VERSION ""

NS_ :

BS_:

BU_: RADAR

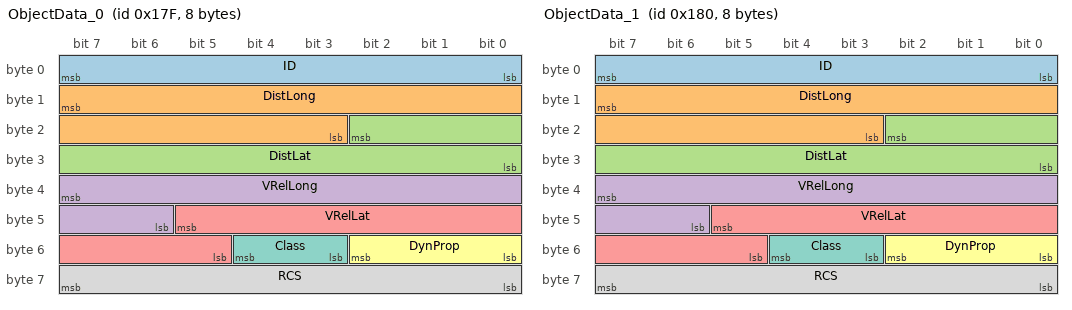
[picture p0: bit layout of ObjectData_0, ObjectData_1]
BO_ 383 ObjectData_0: 8 RADAR
 SG_ ID : 7|8@0+ (1,0) [0|255] "" XXX
 SG_ DistLong : 15|13@0+ (0.2,-500) [-500|1138.2] "m" XXX
 SG_ DistLat : 18|11@0+ (0.2,-204.6) [-204.6|204.8] "m" XXX
 SG_ VRelLong : 39|10@0+ (0.25,-128) [-128|127.75] "m/s" XXX
 SG_ VRelLat : 45|9@0+ (0.25,-64) [-64|63.75] "m/s" XXX
 SG_ DynProp : 50|3@0+ (1,0) [0|7] "" XXX
 SG_ Class : 52|2@0+ (1,0) [0|3] "" XXX
 SG_ RCS : 63|8@0+ (0.5,-64) [-64|63.75] "dBm2" XXX

BO_ 384 ObjectData_1: 8 RADAR
 SG_ ID : 7|8@0+ (1,0) [0|255] "" XXX
 SG_ DistLong : 15|13@0+ (0.2,-500) [-500|1138.2] "m" XXX
 SG_ DistLat : 18|11@0+ (0.2,-204.6) [-204.6|204.8] "m" XXX
 SG_ VRelLong : 39|10@0+ (0.25,-128) [-128|127.75] "m/s" XXX
 SG_ VRelLat : 45|9@0+ (0.25,-64) [-64|63.75] "m/s" XXX
 SG_ DynProp : 50|3@0+ (1,0) [0|7] "" XXX
 SG_ Class : 52|2@0+ (1,0) [0|3] "" XXX
 SG_ RCS : 63|8@0+ (0.5,-64) [-64|63.75] "dBm2" XXX

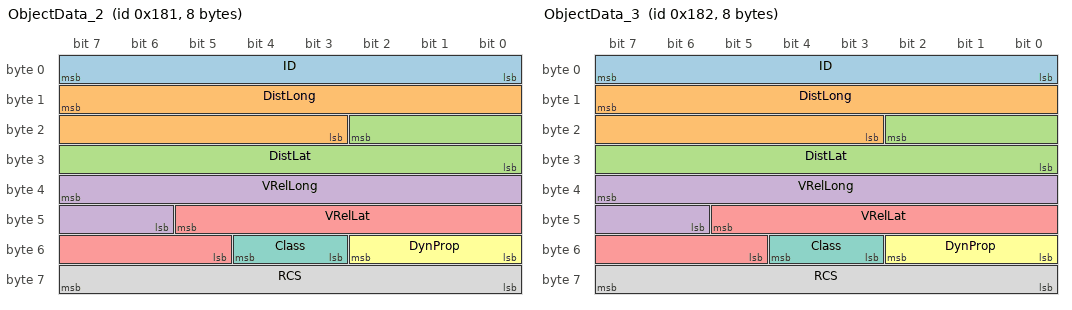
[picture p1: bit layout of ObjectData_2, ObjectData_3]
BO_ 385 ObjectData_2: 8 RADAR
 SG_ ID : 7|8@0+ (1,0) [0|255] "" XXX
 SG_ DistLong : 15|13@0+ (0.2,-500) [-500|1138.2] "m" XXX
 SG_ DistLat : 18|11@0+ (0.2,-204.6) [-204.6|204.8] "m" XXX
 SG_ VRelLong : 39|10@0+ (0.25,-128) [-128|127.75] "m/s" XXX
 SG_ VRelLat : 45|9@0+ (0.25,-64) [-64|63.75] "m/s" XXX
 SG_ DynProp : 50|3@0+ (1,0) [0|7] "" XXX
 SG_ Class : 52|2@0+ (1,0) [0|3] "" XXX
 SG_ RCS : 63|8@0+ (0.5,-64) [-64|63.75] "dBm2" XXX

BO_ 386 ObjectData_3: 8 RADAR
 SG_ ID : 7|8@0+ (1,0) [0|255] "" XXX
 SG_ DistLong : 15|13@0+ (0.2,-500) [-500|1138.2] "m" XXX
 SG_ DistLat : 18|11@0+ (0.2,-204.6) [-204.6|204.8] "m" XXX
 SG_ VRelLong : 39|10@0+ (0.25,-128) [-128|127.75] "m/s" XXX
 SG_ VRelLat : 45|9@0+ (0.25,-64) [-64|63.75] "m/s" XXX
 SG_ DynProp : 50|3@0+ (1,0) [0|7] "" XXX
 SG_ Class : 52|2@0+ (1,0) [0|3] "" XXX
 SG_ RCS : 63|8@0+ (0.5,-64) [-64|63.75] "dBm2" XXX

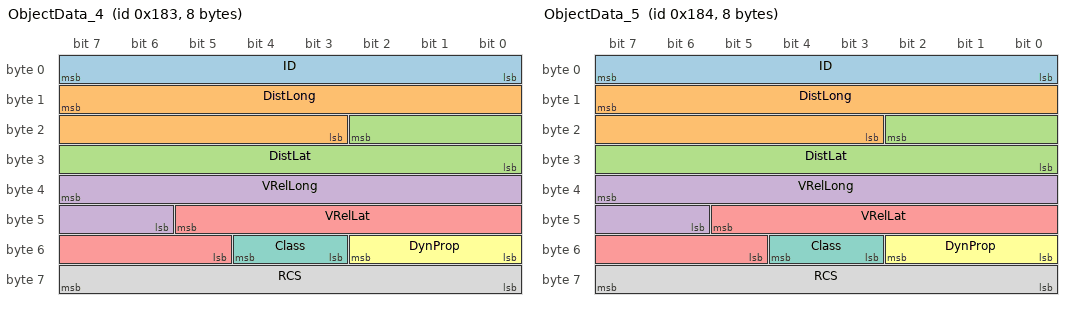
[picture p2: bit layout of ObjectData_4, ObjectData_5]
BO_ 387 ObjectData_4: 8 RADAR
 SG_ ID : 7|8@0+ (1,0) [0|255] "" XXX
 SG_ DistLong : 15|13@0+ (0.2,-500) [-500|1138.2] "m" XXX
 SG_ DistLat : 18|11@0+ (0.2,-204.6) [-204.6|204.8] "m" XXX
 SG_ VRelLong : 39|10@0+ (0.25,-128) [-128|127.75] "m/s" XXX
 SG_ VRelLat : 45|9@0+ (0.25,-64) [-64|63.75] "m/s" XXX
 SG_ DynProp : 50|3@0+ (1,0) [0|7] "" XXX
 SG_ Class : 52|2@0+ (1,0) [0|3] "" XXX
 SG_ RCS : 63|8@0+ (0.5,-64) [-64|63.75] "dBm2" XXX

BO_ 388 ObjectData_5: 8 RADAR
 SG_ ID : 7|8@0+ (1,0) [0|255] "" XXX
 SG_ DistLong : 15|13@0+ (0.2,-500) [-500|1138.2] "m" XXX
 SG_ DistLat : 18|11@0+ (0.2,-204.6) [-204.6|204.8] "m" XXX
 SG_ VRelLong : 39|10@0+ (0.25,-128) [-128|127.75] "m/s" XXX
 SG_ VRelLat : 45|9@0+ (0.25,-64) [-64|63.75] "m/s" XXX
 SG_ DynProp : 50|3@0+ (1,0) [0|7] "" XXX
 SG_ Class : 52|2@0+ (1,0) [0|3] "" XXX
 SG_ RCS : 63|8@0+ (0.5,-64) [-64|63.75] "dBm2" XXX

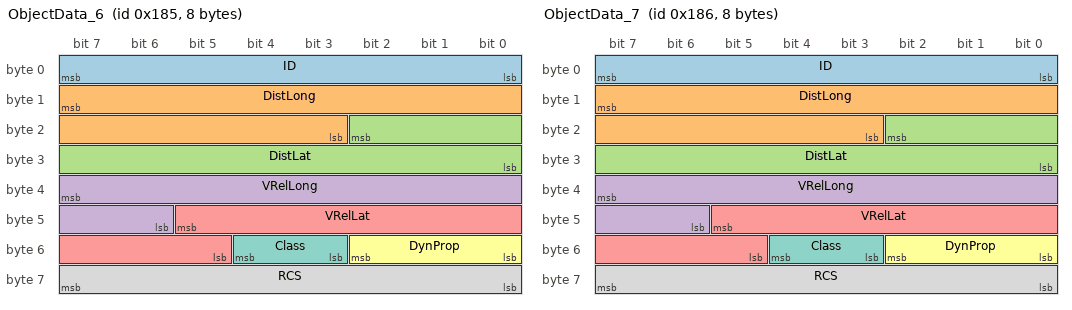
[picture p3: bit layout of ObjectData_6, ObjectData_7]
BO_ 389 ObjectData_6: 8 RADAR
 SG_ ID : 7|8@0+ (1,0) [0|255] "" XXX
 SG_ DistLong : 15|13@0+ (0.2,-500) [-500|1138.2] "m" XXX
 SG_ DistLat : 18|11@0+ (0.2,-204.6) [-204.6|204.8] "m" XXX
 SG_ VRelLong : 39|10@0+ (0.25,-128) [-128|127.75] "m/s" XXX
 SG_ VRelLat : 45|9@0+ (0.25,-64) [-64|63.75] "m/s" XXX
 SG_ DynProp : 50|3@0+ (1,0) [0|7] "" XXX
 SG_ Class : 52|2@0+ (1,0) [0|3] "" XXX
 SG_ RCS : 63|8@0+ (0.5,-64) [-64|63.75] "dBm2" XXX

BO_ 390 ObjectData_7: 8 RADAR
 SG_ ID : 7|8@0+ (1,0) [0|255] "" XXX
 SG_ DistLong : 15|13@0+ (0.2,-500) [-500|1138.2] "m" XXX
 SG_ DistLat : 18|11@0+ (0.2,-204.6) [-204.6|204.8] "m" XXX
 SG_ VRelLong : 39|10@0+ (0.25,-128) [-128|127.75] "m/s" XXX
 SG_ VRelLat : 45|9@0+ (0.25,-64) [-64|63.75] "m/s" XXX
 SG_ DynProp : 50|3@0+ (1,0) [0|7] "" XXX
 SG_ Class : 52|2@0+ (1,0) [0|3] "" XXX
 SG_ RCS : 63|8@0+ (0.5,-64) [-64|63.75] "dBm2" XXX

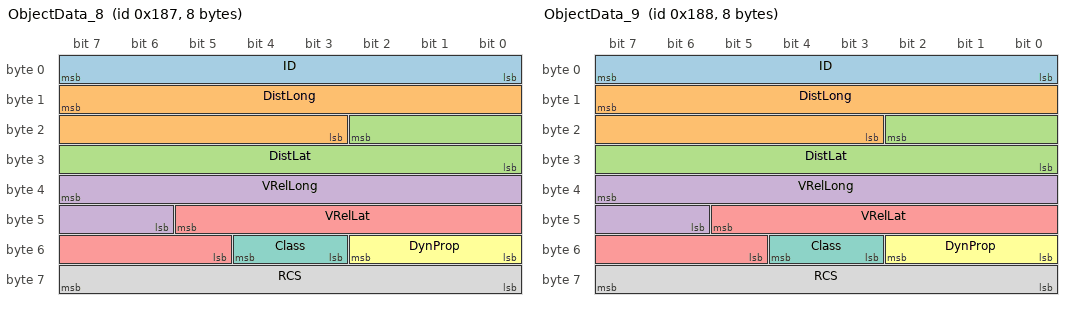
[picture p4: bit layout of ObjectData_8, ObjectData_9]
BO_ 391 ObjectData_8: 8 RADAR
 SG_ ID : 7|8@0+ (1,0) [0|255] "" XXX
 SG_ DistLong : 15|13@0+ (0.2,-500) [-500|1138.2] "m" XXX
 SG_ DistLat : 18|11@0+ (0.2,-204.6) [-204.6|204.8] "m" XXX
 SG_ VRelLong : 39|10@0+ (0.25,-128) [-128|127.75] "m/s" XXX
 SG_ VRelLat : 45|9@0+ (0.25,-64) [-64|63.75] "m/s" XXX
 SG_ DynProp : 50|3@0+ (1,0) [0|7] "" XXX
 SG_ Class : 52|2@0+ (1,0) [0|3] "" XXX
 SG_ RCS : 63|8@0+ (0.5,-64) [-64|63.75] "dBm2" XXX

BO_ 392 ObjectData_9: 8 RADAR
 SG_ ID : 7|8@0+ (1,0) [0|255] "" XXX
 SG_ DistLong : 15|13@0+ (0.2,-500) [-500|1138.2] "m" XXX
 SG_ DistLat : 18|11@0+ (0.2,-204.6) [-204.6|204.8] "m" XXX
 SG_ VRelLong : 39|10@0+ (0.25,-128) [-128|127.75] "m/s" XXX
 SG_ VRelLat : 45|9@0+ (0.25,-64) [-64|63.75] "m/s" XXX
 SG_ DynProp : 50|3@0+ (1,0) [0|7] "" XXX
 SG_ Class : 52|2@0+ (1,0) [0|3] "" XXX
 SG_ RCS : 63|8@0+ (0.5,-64) [-64|63.75] "dBm2" XXX

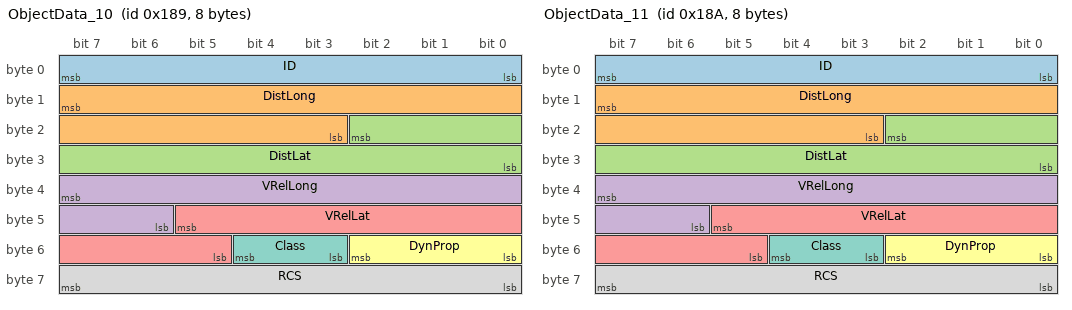
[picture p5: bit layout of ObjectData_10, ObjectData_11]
BO_ 393 ObjectData_10: 8 RADAR
 SG_ ID : 7|8@0+ (1,0) [0|255] "" XXX
 SG_ DistLong : 15|13@0+ (0.2,-500) [-500|1138.2] "m" XXX
 SG_ DistLat : 18|11@0+ (0.2,-204.6) [-204.6|204.8] "m" XXX
 SG_ VRelLong : 39|10@0+ (0.25,-128) [-128|127.75] "m/s" XXX
 SG_ VRelLat : 45|9@0+ (0.25,-64) [-64|63.75] "m/s" XXX
 SG_ DynProp : 50|3@0+ (1,0) [0|7] "" XXX
 SG_ Class : 52|2@0+ (1,0) [0|3] "" XXX
 SG_ RCS : 63|8@0+ (0.5,-64) [-64|63.75] "dBm2" XXX

BO_ 394 ObjectData_11: 8 RADAR
 SG_ ID : 7|8@0+ (1,0) [0|255] "" XXX
 SG_ DistLong : 15|13@0+ (0.2,-500) [-500|1138.2] "m" XXX
 SG_ DistLat : 18|11@0+ (0.2,-204.6) [-204.6|204.8] "m" XXX
 SG_ VRelLong : 39|10@0+ (0.25,-128) [-128|127.75] "m/s" XXX
 SG_ VRelLat : 45|9@0+ (0.25,-64) [-64|63.75] "m/s" XXX
 SG_ DynProp : 50|3@0+ (1,0) [0|7] "" XXX
 SG_ Class : 52|2@0+ (1,0) [0|3] "" XXX
 SG_ RCS : 63|8@0+ (0.5,-64) [-64|63.75] "dBm2" XXX

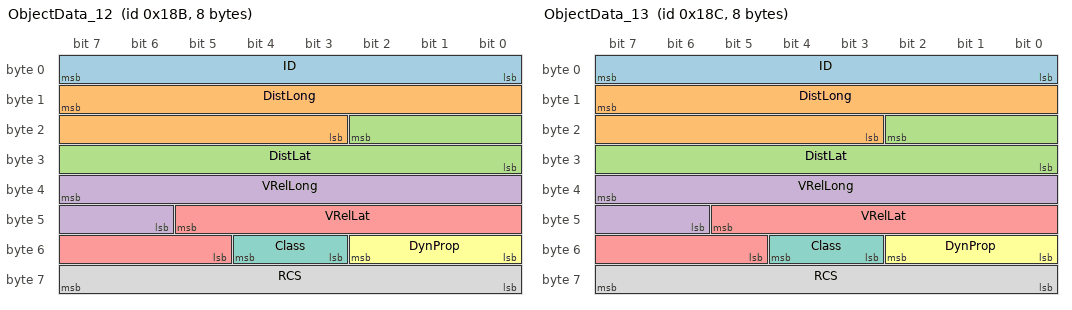
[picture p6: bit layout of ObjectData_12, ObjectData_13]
BO_ 395 ObjectData_12: 8 RADAR
 SG_ ID : 7|8@0+ (1,0) [0|255] "" XXX
 SG_ DistLong : 15|13@0+ (0.2,-500) [-500|1138.2] "m" XXX
 SG_ DistLat : 18|11@0+ (0.2,-204.6) [-204.6|204.8] "m" XXX
 SG_ VRelLong : 39|10@0+ (0.25,-128) [-128|127.75] "m/s" XXX
 SG_ VRelLat : 45|9@0+ (0.25,-64) [-64|63.75] "m/s" XXX
 SG_ DynProp : 50|3@0+ (1,0) [0|7] "" XXX
 SG_ Class : 52|2@0+ (1,0) [0|3] "" XXX
 SG_ RCS : 63|8@0+ (0.5,-64) [-64|63.75] "dBm2" XXX

BO_ 396 ObjectData_13: 8 RADAR
 SG_ ID : 7|8@0+ (1,0) [0|255] "" XXX
 SG_ DistLong : 15|13@0+ (0.2,-500) [-500|1138.2] "m" XXX
 SG_ DistLat : 18|11@0+ (0.2,-204.6) [-204.6|204.8] "m" XXX
 SG_ VRelLong : 39|10@0+ (0.25,-128) [-128|127.75] "m/s" XXX
 SG_ VRelLat : 45|9@0+ (0.25,-64) [-64|63.75] "m/s" XXX
 SG_ DynProp : 50|3@0+ (1,0) [0|7] "" XXX
 SG_ Class : 52|2@0+ (1,0) [0|3] "" XXX
 SG_ RCS : 63|8@0+ (0.5,-64) [-64|63.75] "dBm2" XXX

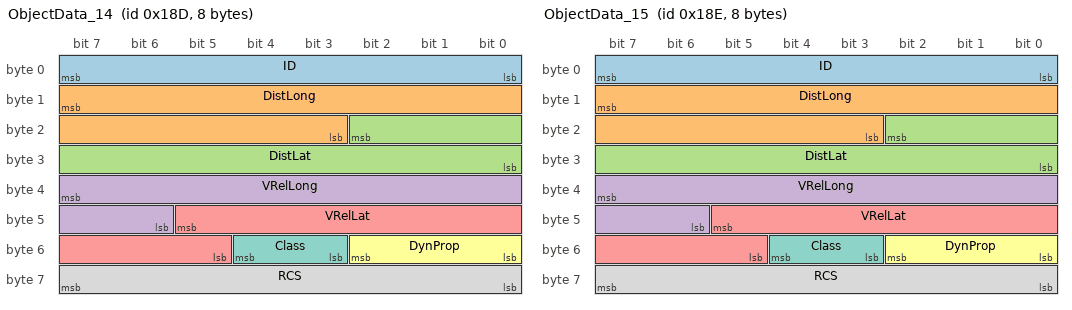
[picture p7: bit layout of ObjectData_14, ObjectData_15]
BO_ 397 ObjectData_14: 8 RADAR
 SG_ ID : 7|8@0+ (1,0) [0|255] "" XXX
 SG_ DistLong : 15|13@0+ (0.2,-500) [-500|1138.2] "m" XXX
 SG_ DistLat : 18|11@0+ (0.2,-204.6) [-204.6|204.8] "m" XXX
 SG_ VRelLong : 39|10@0+ (0.25,-128) [-128|127.75] "m/s" XXX
 SG_ VRelLat : 45|9@0+ (0.25,-64) [-64|63.75] "m/s" XXX
 SG_ DynProp : 50|3@0+ (1,0) [0|7] "" XXX
 SG_ Class : 52|2@0+ (1,0) [0|3] "" XXX
 SG_ RCS : 63|8@0+ (0.5,-64) [-64|63.75] "dBm2" XXX

BO_ 398 ObjectData_15: 8 RADAR
 SG_ ID : 7|8@0+ (1,0) [0|255] "" XXX
 SG_ DistLong : 15|13@0+ (0.2,-500) [-500|1138.2] "m" XXX
 SG_ DistLat : 18|11@0+ (0.2,-204.6) [-204.6|204.8] "m" XXX
 SG_ VRelLong : 39|10@0+ (0.25,-128) [-128|127.75] "m/s" XXX
 SG_ VRelLat : 45|9@0+ (0.25,-64) [-64|63.75] "m/s" XXX
 SG_ DynProp : 50|3@0+ (1,0) [0|7] "" XXX
 SG_ Class : 52|2@0+ (1,0) [0|3] "" XXX
 SG_ RCS : 63|8@0+ (0.5,-64) [-64|63.75] "dBm2" XXX

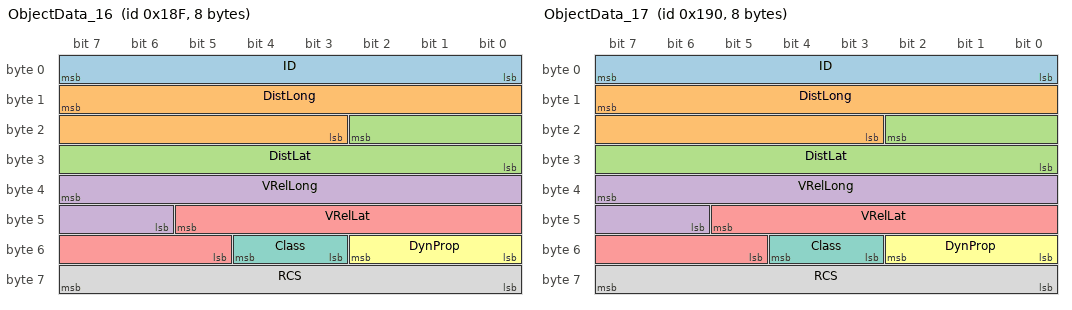
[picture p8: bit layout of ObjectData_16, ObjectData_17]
BO_ 399 ObjectData_16: 8 RADAR
 SG_ ID : 7|8@0+ (1,0) [0|255] "" XXX
 SG_ DistLong : 15|13@0+ (0.2,-500) [-500|1138.2] "m" XXX
 SG_ DistLat : 18|11@0+ (0.2,-204.6) [-204.6|204.8] "m" XXX
 SG_ VRelLong : 39|10@0+ (0.25,-128) [-128|127.75] "m/s" XXX
 SG_ VRelLat : 45|9@0+ (0.25,-64) [-64|63.75] "m/s" XXX
 SG_ DynProp : 50|3@0+ (1,0) [0|7] "" XXX
 SG_ Class : 52|2@0+ (1,0) [0|3] "" XXX
 SG_ RCS : 63|8@0+ (0.5,-64) [-64|63.75] "dBm2" XXX

BO_ 400 ObjectData_17: 8 RADAR
 SG_ ID : 7|8@0+ (1,0) [0|255] "" XXX
 SG_ DistLong : 15|13@0+ (0.2,-500) [-500|1138.2] "m" XXX
 SG_ DistLat : 18|11@0+ (0.2,-204.6) [-204.6|204.8] "m" XXX
 SG_ VRelLong : 39|10@0+ (0.25,-128) [-128|127.75] "m/s" XXX
 SG_ VRelLat : 45|9@0+ (0.25,-64) [-64|63.75] "m/s" XXX
 SG_ DynProp : 50|3@0+ (1,0) [0|7] "" XXX
 SG_ Class : 52|2@0+ (1,0) [0|3] "" XXX
 SG_ RCS : 63|8@0+ (0.5,-64) [-64|63.75] "dBm2" XXX

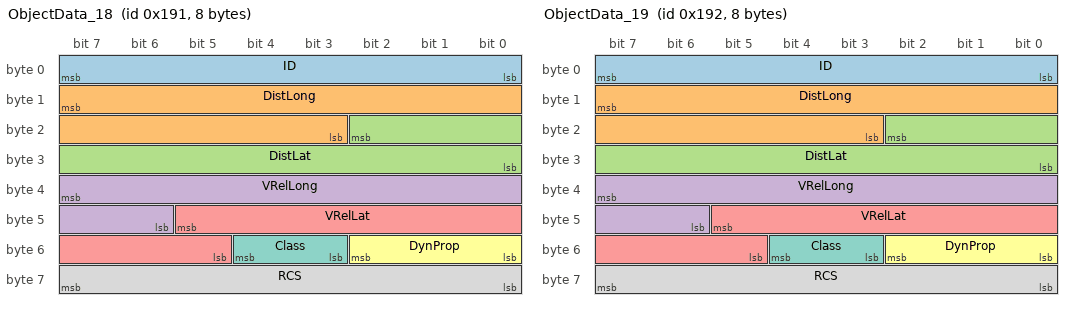
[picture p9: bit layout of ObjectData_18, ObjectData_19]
BO_ 401 ObjectData_18: 8 RADAR
 SG_ ID : 7|8@0+ (1,0) [0|255] "" XXX
 SG_ DistLong : 15|13@0+ (0.2,-500) [-500|1138.2] "m" XXX
 SG_ DistLat : 18|11@0+ (0.2,-204.6) [-204.6|204.8] "m" XXX
 SG_ VRelLong : 39|10@0+ (0.25,-128) [-128|127.75] "m/s" XXX
 SG_ VRelLat : 45|9@0+ (0.25,-64) [-64|63.75] "m/s" XXX
 SG_ DynProp : 50|3@0+ (1,0) [0|7] "" XXX
 SG_ Class : 52|2@0+ (1,0) [0|3] "" XXX
 SG_ RCS : 63|8@0+ (0.5,-64) [-64|63.75] "dBm2" XXX

BO_ 402 ObjectData_19: 8 RADAR
 SG_ ID : 7|8@0+ (1,0) [0|255] "" XXX
 SG_ DistLong : 15|13@0+ (0.2,-500) [-500|1138.2] "m" XXX
 SG_ DistLat : 18|11@0+ (0.2,-204.6) [-204.6|204.8] "m" XXX
 SG_ VRelLong : 39|10@0+ (0.25,-128) [-128|127.75] "m/s" XXX
 SG_ VRelLat : 45|9@0+ (0.25,-64) [-64|63.75] "m/s" XXX
 SG_ DynProp : 50|3@0+ (1,0) [0|7] "" XXX
 SG_ Class : 52|2@0+ (1,0) [0|3] "" XXX
 SG_ RCS : 63|8@0+ (0.5,-64) [-64|63.75] "dBm2" XXX

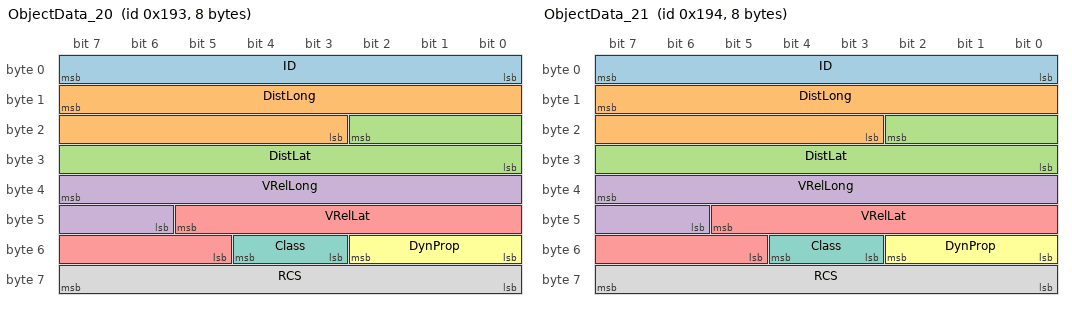
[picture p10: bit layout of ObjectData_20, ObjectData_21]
BO_ 403 ObjectData_20: 8 RADAR
 SG_ ID : 7|8@0+ (1,0) [0|255] "" XXX
 SG_ DistLong : 15|13@0+ (0.2,-500) [-500|1138.2] "m" XXX
 SG_ DistLat : 18|11@0+ (0.2,-204.6) [-204.6|204.8] "m" XXX
 SG_ VRelLong : 39|10@0+ (0.25,-128) [-128|127.75] "m/s" XXX
 SG_ VRelLat : 45|9@0+ (0.25,-64) [-64|63.75] "m/s" XXX
 SG_ DynProp : 50|3@0+ (1,0) [0|7] "" XXX
 SG_ Class : 52|2@0+ (1,0) [0|3] "" XXX
 SG_ RCS : 63|8@0+ (0.5,-64) [-64|63.75] "dBm2" XXX

BO_ 404 ObjectData_21: 8 RADAR
 SG_ ID : 7|8@0+ (1,0) [0|255] "" XXX
 SG_ DistLong : 15|13@0+ (0.2,-500) [-500|1138.2] "m" XXX
 SG_ DistLat : 18|11@0+ (0.2,-204.6) [-204.6|204.8] "m" XXX
 SG_ VRelLong : 39|10@0+ (0.25,-128) [-128|127.75] "m/s" XXX
 SG_ VRelLat : 45|9@0+ (0.25,-64) [-64|63.75] "m/s" XXX
 SG_ DynProp : 50|3@0+ (1,0) [0|7] "" XXX
 SG_ Class : 52|2@0+ (1,0) [0|3] "" XXX
 SG_ RCS : 63|8@0+ (0.5,-64) [-64|63.75] "dBm2" XXX

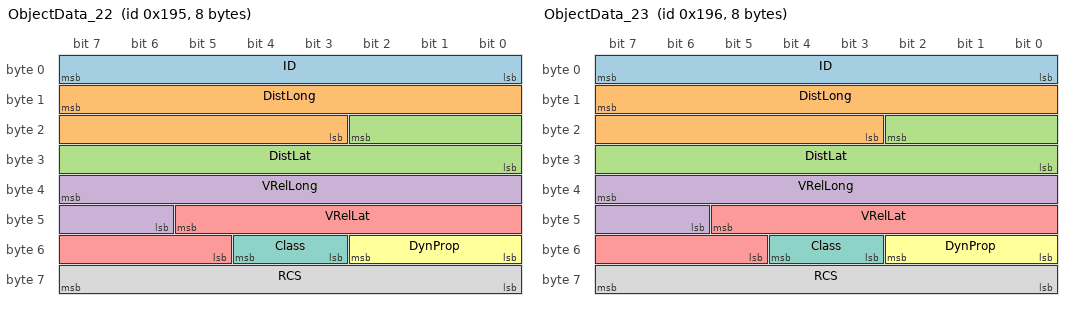
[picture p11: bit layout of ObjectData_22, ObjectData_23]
BO_ 405 ObjectData_22: 8 RADAR
 SG_ ID : 7|8@0+ (1,0) [0|255] "" XXX
 SG_ DistLong : 15|13@0+ (0.2,-500) [-500|1138.2] "m" XXX
 SG_ DistLat : 18|11@0+ (0.2,-204.6) [-204.6|204.8] "m" XXX
 SG_ VRelLong : 39|10@0+ (0.25,-128) [-128|127.75] "m/s" XXX
 SG_ VRelLat : 45|9@0+ (0.25,-64) [-64|63.75] "m/s" XXX
 SG_ DynProp : 50|3@0+ (1,0) [0|7] "" XXX
 SG_ Class : 52|2@0+ (1,0) [0|3] "" XXX
 SG_ RCS : 63|8@0+ (0.5,-64) [-64|63.75] "dBm2" XXX

BO_ 406 ObjectData_23: 8 RADAR
 SG_ ID : 7|8@0+ (1,0) [0|255] "" XXX
 SG_ DistLong : 15|13@0+ (0.2,-500) [-500|1138.2] "m" XXX
 SG_ DistLat : 18|11@0+ (0.2,-204.6) [-204.6|204.8] "m" XXX
 SG_ VRelLong : 39|10@0+ (0.25,-128) [-128|127.75] "m/s" XXX
 SG_ VRelLat : 45|9@0+ (0.25,-64) [-64|63.75] "m/s" XXX
 SG_ DynProp : 50|3@0+ (1,0) [0|7] "" XXX
 SG_ Class : 52|2@0+ (1,0) [0|3] "" XXX
 SG_ RCS : 63|8@0+ (0.5,-64) [-64|63.75] "dBm2" XXX

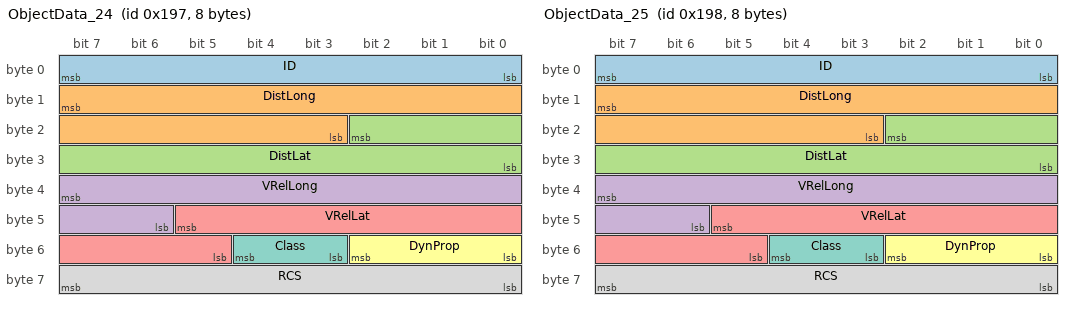
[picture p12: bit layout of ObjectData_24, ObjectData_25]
BO_ 407 ObjectData_24: 8 RADAR
 SG_ ID : 7|8@0+ (1,0) [0|255] "" XXX
 SG_ DistLong : 15|13@0+ (0.2,-500) [-500|1138.2] "m" XXX
 SG_ DistLat : 18|11@0+ (0.2,-204.6) [-204.6|204.8] "m" XXX
 SG_ VRelLong : 39|10@0+ (0.25,-128) [-128|127.75] "m/s" XXX
 SG_ VRelLat : 45|9@0+ (0.25,-64) [-64|63.75] "m/s" XXX
 SG_ DynProp : 50|3@0+ (1,0) [0|7] "" XXX
 SG_ Class : 52|2@0+ (1,0) [0|3] "" XXX
 SG_ RCS : 63|8@0+ (0.5,-64) [-64|63.75] "dBm2" XXX

BO_ 408 ObjectData_25: 8 RADAR
 SG_ ID : 7|8@0+ (1,0) [0|255] "" XXX
 SG_ DistLong : 15|13@0+ (0.2,-500) [-500|1138.2] "m" XXX
 SG_ DistLat : 18|11@0+ (0.2,-204.6) [-204.6|204.8] "m" XXX
 SG_ VRelLong : 39|10@0+ (0.25,-128) [-128|127.75] "m/s" XXX
 SG_ VRelLat : 45|9@0+ (0.25,-64) [-64|63.75] "m/s" XXX
 SG_ DynProp : 50|3@0+ (1,0) [0|7] "" XXX
 SG_ Class : 52|2@0+ (1,0) [0|3] "" XXX
 SG_ RCS : 63|8@0+ (0.5,-64) [-64|63.75] "dBm2" XXX

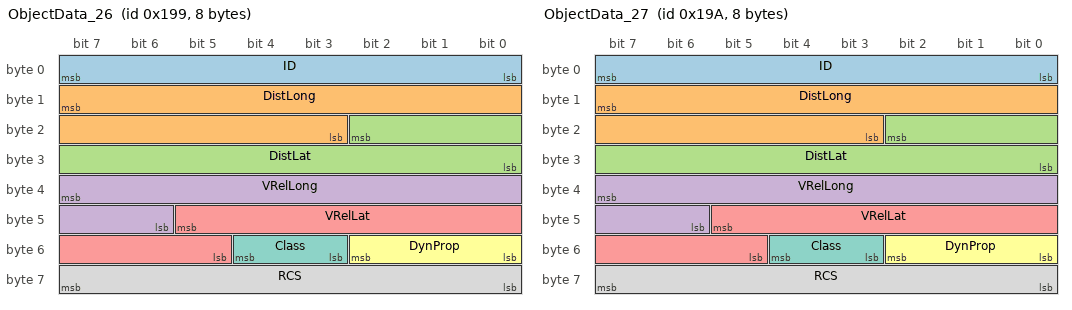
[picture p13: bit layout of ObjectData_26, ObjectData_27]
BO_ 409 ObjectData_26: 8 RADAR
 SG_ ID : 7|8@0+ (1,0) [0|255] "" XXX
 SG_ DistLong : 15|13@0+ (0.2,-500) [-500|1138.2] "m" XXX
 SG_ DistLat : 18|11@0+ (0.2,-204.6) [-204.6|204.8] "m" XXX
 SG_ VRelLong : 39|10@0+ (0.25,-128) [-128|127.75] "m/s" XXX
 SG_ VRelLat : 45|9@0+ (0.25,-64) [-64|63.75] "m/s" XXX
 SG_ DynProp : 50|3@0+ (1,0) [0|7] "" XXX
 SG_ Class : 52|2@0+ (1,0) [0|3] "" XXX
 SG_ RCS : 63|8@0+ (0.5,-64) [-64|63.75] "dBm2" XXX

BO_ 410 ObjectData_27: 8 RADAR
 SG_ ID : 7|8@0+ (1,0) [0|255] "" XXX
 SG_ DistLong : 15|13@0+ (0.2,-500) [-500|1138.2] "m" XXX
 SG_ DistLat : 18|11@0+ (0.2,-204.6) [-204.6|204.8] "m" XXX
 SG_ VRelLong : 39|10@0+ (0.25,-128) [-128|127.75] "m/s" XXX
 SG_ VRelLat : 45|9@0+ (0.25,-64) [-64|63.75] "m/s" XXX
 SG_ DynProp : 50|3@0+ (1,0) [0|7] "" XXX
 SG_ Class : 52|2@0+ (1,0) [0|3] "" XXX
 SG_ RCS : 63|8@0+ (0.5,-64) [-64|63.75] "dBm2" XXX

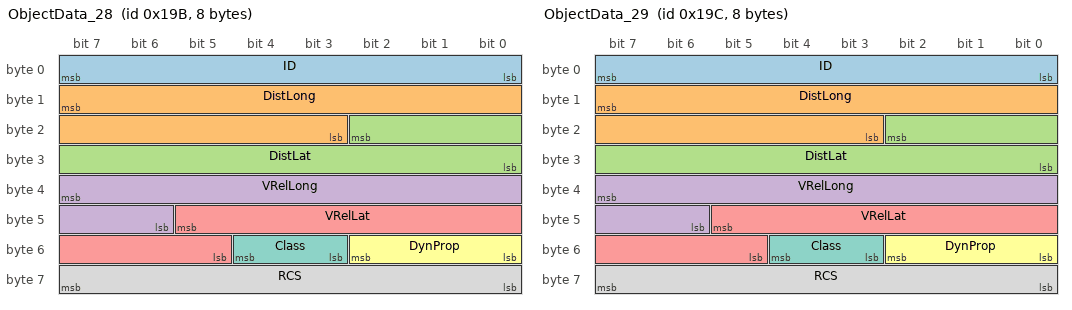
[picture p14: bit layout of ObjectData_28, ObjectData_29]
BO_ 411 ObjectData_28: 8 RADAR
 SG_ ID : 7|8@0+ (1,0) [0|255] "" XXX
 SG_ DistLong : 15|13@0+ (0.2,-500) [-500|1138.2] "m" XXX
 SG_ DistLat : 18|11@0+ (0.2,-204.6) [-204.6|204.8] "m" XXX
 SG_ VRelLong : 39|10@0+ (0.25,-128) [-128|127.75] "m/s" XXX
 SG_ VRelLat : 45|9@0+ (0.25,-64) [-64|63.75] "m/s" XXX
 SG_ DynProp : 50|3@0+ (1,0) [0|7] "" XXX
 SG_ Class : 52|2@0+ (1,0) [0|3] "" XXX
 SG_ RCS : 63|8@0+ (0.5,-64) [-64|63.75] "dBm2" XXX

BO_ 412 ObjectData_29: 8 RADAR
 SG_ ID : 7|8@0+ (1,0) [0|255] "" XXX
 SG_ DistLong : 15|13@0+ (0.2,-500) [-500|1138.2] "m" XXX
 SG_ DistLat : 18|11@0+ (0.2,-204.6) [-204.6|204.8] "m" XXX
 SG_ VRelLong : 39|10@0+ (0.25,-128) [-128|127.75] "m/s" XXX
 SG_ VRelLat : 45|9@0+ (0.25,-64) [-64|63.75] "m/s" XXX
 SG_ DynProp : 50|3@0+ (1,0) [0|7] "" XXX
 SG_ Class : 52|2@0+ (1,0) [0|3] "" XXX
 SG_ RCS : 63|8@0+ (0.5,-64) [-64|63.75] "dBm2" XXX

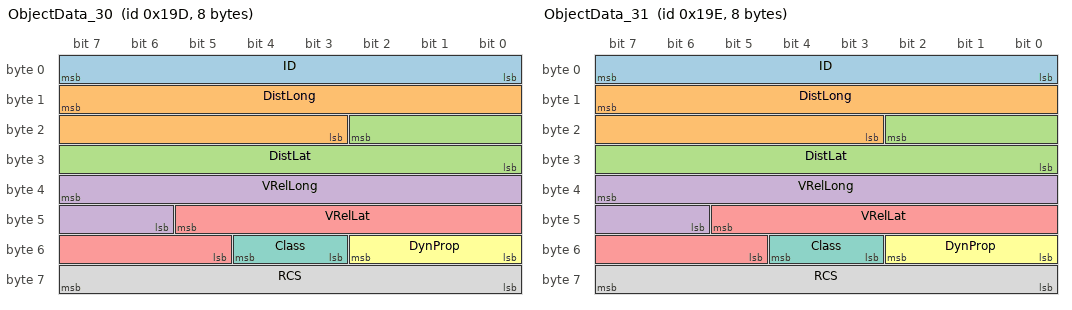
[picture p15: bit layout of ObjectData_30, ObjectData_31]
BO_ 413 ObjectData_30: 8 RADAR
 SG_ ID : 7|8@0+ (1,0) [0|255] "" XXX
 SG_ DistLong : 15|13@0+ (0.2,-500) [-500|1138.2] "m" XXX
 SG_ DistLat : 18|11@0+ (0.2,-204.6) [-204.6|204.8] "m" XXX
 SG_ VRelLong : 39|10@0+ (0.25,-128) [-128|127.75] "m/s" XXX
 SG_ VRelLat : 45|9@0+ (0.25,-64) [-64|63.75] "m/s" XXX
 SG_ DynProp : 50|3@0+ (1,0) [0|7] "" XXX
 SG_ Class : 52|2@0+ (1,0) [0|3] "" XXX
 SG_ RCS : 63|8@0+ (0.5,-64) [-64|63.75] "dBm2" XXX

BO_ 414 ObjectData_31: 8 RADAR
 SG_ ID : 7|8@0+ (1,0) [0|255] "" XXX
 SG_ DistLong : 15|13@0+ (0.2,-500) [-500|1138.2] "m" XXX
 SG_ DistLat : 18|11@0+ (0.2,-204.6) [-204.6|204.8] "m" XXX
 SG_ VRelLong : 39|10@0+ (0.25,-128) [-128|127.75] "m/s" XXX
 SG_ VRelLat : 45|9@0+ (0.25,-64) [-64|63.75] "m/s" XXX
 SG_ DynProp : 50|3@0+ (1,0) [0|7] "" XXX
 SG_ Class : 52|2@0+ (1,0) [0|3] "" XXX
 SG_ RCS : 63|8@0+ (0.5,-64) [-64|63.75] "dBm2" XXX

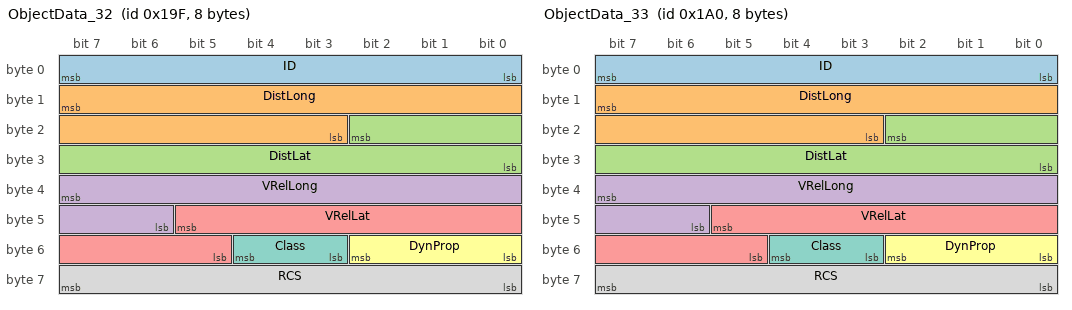
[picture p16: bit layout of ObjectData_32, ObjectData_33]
BO_ 415 ObjectData_32: 8 RADAR
 SG_ ID : 7|8@0+ (1,0) [0|255] "" XXX
 SG_ DistLong : 15|13@0+ (0.2,-500) [-500|1138.2] "m" XXX
 SG_ DistLat : 18|11@0+ (0.2,-204.6) [-204.6|204.8] "m" XXX
 SG_ VRelLong : 39|10@0+ (0.25,-128) [-128|127.75] "m/s" XXX
 SG_ VRelLat : 45|9@0+ (0.25,-64) [-64|63.75] "m/s" XXX
 SG_ DynProp : 50|3@0+ (1,0) [0|7] "" XXX
 SG_ Class : 52|2@0+ (1,0) [0|3] "" XXX
 SG_ RCS : 63|8@0+ (0.5,-64) [-64|63.75] "dBm2" XXX

BO_ 416 ObjectData_33: 8 RADAR
 SG_ ID : 7|8@0+ (1,0) [0|255] "" XXX
 SG_ DistLong : 15|13@0+ (0.2,-500) [-500|1138.2] "m" XXX
 SG_ DistLat : 18|11@0+ (0.2,-204.6) [-204.6|204.8] "m" XXX
 SG_ VRelLong : 39|10@0+ (0.25,-128) [-128|127.75] "m/s" XXX
 SG_ VRelLat : 45|9@0+ (0.25,-64) [-64|63.75] "m/s" XXX
 SG_ DynProp : 50|3@0+ (1,0) [0|7] "" XXX
 SG_ Class : 52|2@0+ (1,0) [0|3] "" XXX
 SG_ RCS : 63|8@0+ (0.5,-64) [-64|63.75] "dBm2" XXX

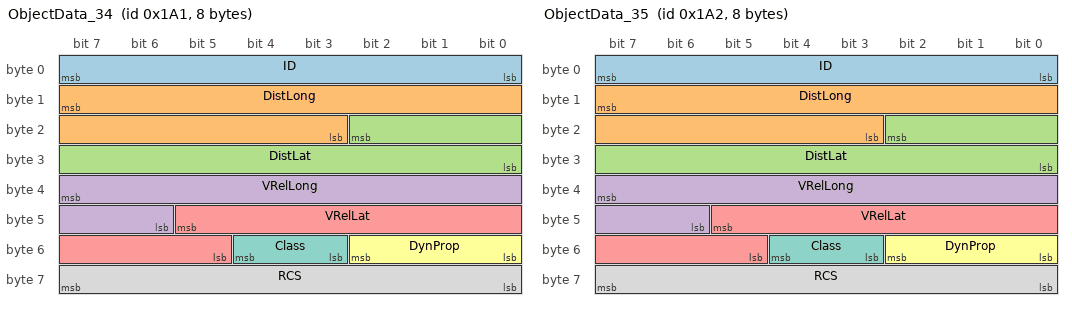
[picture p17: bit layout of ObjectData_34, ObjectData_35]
BO_ 417 ObjectData_34: 8 RADAR
 SG_ ID : 7|8@0+ (1,0) [0|255] "" XXX
 SG_ DistLong : 15|13@0+ (0.2,-500) [-500|1138.2] "m" XXX
 SG_ DistLat : 18|11@0+ (0.2,-204.6) [-204.6|204.8] "m" XXX
 SG_ VRelLong : 39|10@0+ (0.25,-128) [-128|127.75] "m/s" XXX
 SG_ VRelLat : 45|9@0+ (0.25,-64) [-64|63.75] "m/s" XXX
 SG_ DynProp : 50|3@0+ (1,0) [0|7] "" XXX
 SG_ Class : 52|2@0+ (1,0) [0|3] "" XXX
 SG_ RCS : 63|8@0+ (0.5,-64) [-64|63.75] "dBm2" XXX

BO_ 418 ObjectData_35: 8 RADAR
 SG_ ID : 7|8@0+ (1,0) [0|255] "" XXX
 SG_ DistLong : 15|13@0+ (0.2,-500) [-500|1138.2] "m" XXX
 SG_ DistLat : 18|11@0+ (0.2,-204.6) [-204.6|204.8] "m" XXX
 SG_ VRelLong : 39|10@0+ (0.25,-128) [-128|127.75] "m/s" XXX
 SG_ VRelLat : 45|9@0+ (0.25,-64) [-64|63.75] "m/s" XXX
 SG_ DynProp : 50|3@0+ (1,0) [0|7] "" XXX
 SG_ Class : 52|2@0+ (1,0) [0|3] "" XXX
 SG_ RCS : 63|8@0+ (0.5,-64) [-64|63.75] "dBm2" XXX

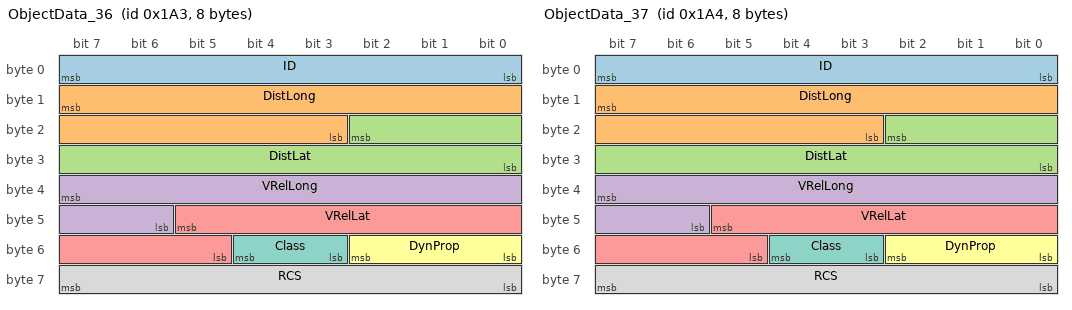
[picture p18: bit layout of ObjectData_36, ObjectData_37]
BO_ 419 ObjectData_36: 8 RADAR
 SG_ ID : 7|8@0+ (1,0) [0|255] "" XXX
 SG_ DistLong : 15|13@0+ (0.2,-500) [-500|1138.2] "m" XXX
 SG_ DistLat : 18|11@0+ (0.2,-204.6) [-204.6|204.8] "m" XXX
 SG_ VRelLong : 39|10@0+ (0.25,-128) [-128|127.75] "m/s" XXX
 SG_ VRelLat : 45|9@0+ (0.25,-64) [-64|63.75] "m/s" XXX
 SG_ DynProp : 50|3@0+ (1,0) [0|7] "" XXX
 SG_ Class : 52|2@0+ (1,0) [0|3] "" XXX
 SG_ RCS : 63|8@0+ (0.5,-64) [-64|63.75] "dBm2" XXX

BO_ 420 ObjectData_37: 8 RADAR
 SG_ ID : 7|8@0+ (1,0) [0|255] "" XXX
 SG_ DistLong : 15|13@0+ (0.2,-500) [-500|1138.2] "m" XXX
 SG_ DistLat : 18|11@0+ (0.2,-204.6) [-204.6|204.8] "m" XXX
 SG_ VRelLong : 39|10@0+ (0.25,-128) [-128|127.75] "m/s" XXX
 SG_ VRelLat : 45|9@0+ (0.25,-64) [-64|63.75] "m/s" XXX
 SG_ DynProp : 50|3@0+ (1,0) [0|7] "" XXX
 SG_ Class : 52|2@0+ (1,0) [0|3] "" XXX
 SG_ RCS : 63|8@0+ (0.5,-64) [-64|63.75] "dBm2" XXX

BO_ 421 ObjectData_38: 8 RADAR
 SG_ ID : 7|8@0+ (1,0) [0|255] "" XXX
 SG_ DistLong : 15|13@0+ (0.2,-500) [-500|1138.2] "m" XXX
 SG_ DistLat : 18|11@0+ (0.2,-204.6) [-204.6|204.8] "m" XXX
 SG_ VRelLong : 39|10@0+ (0.25,-128) [-128|127.75] "m/s" XXX
 SG_ VRelLat : 45|9@0+ (0.25,-64) [-64|63.75] "m/s" XXX
 SG_ DynProp : 50|3@0+ (1,0) [0|7] "" XXX
 SG_ Class : 52|2@0+ (1,0) [0|3] "" XXX
 SG_ RCS : 63|8@0+ (0.5,-64) [-64|63.75] "dBm2" XXX

BO_ 422 ObjectData_39: 8 RADAR
 SG_ ID : 7|8@0+ (1,0) [0|255] "" XXX
 SG_ DistLong : 15|13@0+ (0.2,-500) [-500|1138.2] "m" XXX
 SG_ DistLat : 18|11@0+ (0.2,-204.6) [-204.6|204.8] "m" XXX
 SG_ VRelLong : 39|10@0+ (0.25,-128) [-128|127.75] "m/s" XXX
 SG_ VRelLat : 45|9@0+ (0.25,-64) [-64|63.75] "m/s" XXX
 SG_ DynProp : 50|3@0+ (1,0) [0|7] "" XXX
 SG_ Class : 52|2@0+ (1,0) [0|3] "" XXX
 SG_ RCS : 63|8@0+ (0.5,-64) [-64|63.75] "dBm2" XXX

BO_ 423 ObjectData_40: 8 RADAR
 SG_ ID : 7|8@0+ (1,0) [0|255] "" XXX
 SG_ DistLong : 15|13@0+ (0.2,-500) [-500|1138.2] "m" XXX
 SG_ DistLat : 18|11@0+ (0.2,-204.6) [-204.6|204.8] "m" XXX
 SG_ VRelLong : 39|10@0+ (0.25,-128) [-128|127.75] "m/s" XXX
 SG_ VRelLat : 45|9@0+ (0.25,-64) [-64|63.75] "m/s" XXX
 SG_ DynProp : 50|3@0+ (1,0) [0|7] "" XXX
 SG_ Class : 52|2@0+ (1,0) [0|3] "" XXX
 SG_ RCS : 63|8@0+ (0.5,-64) [-64|63.75] "dBm2" XXX

BO_ 424 ObjectData_41: 8 RADAR
 SG_ ID : 7|8@0+ (1,0) [0|255] "" XXX
 SG_ DistLong : 15|13@0+ (0.2,-500) [-500|1138.2] "m" XXX
 SG_ DistLat : 18|11@0+ (0.2,-204.6) [-204.6|204.8] "m" XXX
 SG_ VRelLong : 39|10@0+ (0.25,-128) [-128|127.75] "m/s" XXX
 SG_ VRelLat : 45|9@0+ (0.25,-64) [-64|63.75] "m/s" XXX
 SG_ DynProp : 50|3@0+ (1,0) [0|7] "" XXX
 SG_ Class : 52|2@0+ (1,0) [0|3] "" XXX
 SG_ RCS : 63|8@0+ (0.5,-64) [-64|63.75] "dBm2" XXX

BO_ 425 ObjectData_42: 8 RADAR
 SG_ ID : 7|8@0+ (1,0) [0|255] "" XXX
 SG_ DistLong : 15|13@0+ (0.2,-500) [-500|1138.2] "m" XXX
 SG_ DistLat : 18|11@0+ (0.2,-204.6) [-204.6|204.8] "m" XXX
 SG_ VRelLong : 39|10@0+ (0.25,-128) [-128|127.75] "m/s" XXX
 SG_ VRelLat : 45|9@0+ (0.25,-64) [-64|63.75] "m/s" XXX
 SG_ DynProp : 50|3@0+ (1,0) [0|7] "" XXX
 SG_ Class : 52|2@0+ (1,0) [0|3] "" XXX
 SG_ RCS : 63|8@0+ (0.5,-64) [-64|63.75] "dBm2" XXX

BO_ 426 ObjectData_43: 8 RADAR
 SG_ ID : 7|8@0+ (1,0) [0|255] "" XXX
 SG_ DistLong : 15|13@0+ (0.2,-500) [-500|1138.2] "m" XXX
 SG_ DistLat : 18|11@0+ (0.2,-204.6) [-204.6|204.8] "m" XXX
 SG_ VRelLong : 39|10@0+ (0.25,-128) [-128|127.75] "m/s" XXX
 SG_ VRelLat : 45|9@0+ (0.25,-64) [-64|63.75] "m/s" XXX
 SG_ DynProp : 50|3@0+ (1,0) [0|7] "" XXX
 SG_ Class : 52|2@0+ (1,0) [0|3] "" XXX
 SG_ RCS : 63|8@0+ (0.5,-64) [-64|63.75] "dBm2" XXX

BO_ 427 ObjectData_44: 8 RADAR
 SG_ ID : 7|8@0+ (1,0) [0|255] "" XXX
 SG_ DistLong : 15|13@0+ (0.2,-500) [-500|1138.2] "m" XXX
 SG_ DistLat : 18|11@0+ (0.2,-204.6) [-204.6|204.8] "m" XXX
 SG_ VRelLong : 39|10@0+ (0.25,-128) [-128|127.75] "m/s" XXX
 SG_ VRelLat : 45|9@0+ (0.25,-64) [-64|63.75] "m/s" XXX
 SG_ DynProp : 50|3@0+ (1,0) [0|7] "" XXX
 SG_ Class : 52|2@0+ (1,0) [0|3] "" XXX
 SG_ RCS : 63|8@0+ (0.5,-64) [-64|63.75] "dBm2" XXX

BO_ 428 ObjectData_45: 8 RADAR
 SG_ ID : 7|8@0+ (1,0) [0|255] "" XXX
 SG_ DistLong : 15|13@0+ (0.2,-500) [-500|1138.2] "m" XXX
 SG_ DistLat : 18|11@0+ (0.2,-204.6) [-204.6|204.8] "m" XXX
 SG_ VRelLong : 39|10@0+ (0.25,-128) [-128|127.75] "m/s" XXX
 SG_ VRelLat : 45|9@0+ (0.25,-64) [-64|63.75] "m/s" XXX
 SG_ DynProp : 50|3@0+ (1,0) [0|7] "" XXX
 SG_ Class : 52|2@0+ (1,0) [0|3] "" XXX
 SG_ RCS : 63|8@0+ (0.5,-64) [-64|63.75] "dBm2" XXX

BO_ 429 ObjectData_46: 8 RADAR
 SG_ ID : 7|8@0+ (1,0) [0|255] "" XXX
 SG_ DistLong : 15|13@0+ (0.2,-500) [-500|1138.2] "m" XXX
 SG_ DistLat : 18|11@0+ (0.2,-204.6) [-204.6|204.8] "m" XXX
 SG_ VRelLong : 39|10@0+ (0.25,-128) [-128|127.75] "m/s" XXX
 SG_ VRelLat : 45|9@0+ (0.25,-64) [-64|63.75] "m/s" XXX
 SG_ DynProp : 50|3@0+ (1,0) [0|7] "" XXX
 SG_ Class : 52|2@0+ (1,0) [0|3] "" XXX
 SG_ RCS : 63|8@0+ (0.5,-64) [-64|63.75] "dBm2" XXX

BO_ 430 ObjectData_47: 8 RADAR
 SG_ ID : 7|8@0+ (1,0) [0|255] "" XXX
 SG_ DistLong : 15|13@0+ (0.2,-500) [-500|1138.2] "m" XXX
 SG_ DistLat : 18|11@0+ (0.2,-204.6) [-204.6|204.8] "m" XXX
 SG_ VRelLong : 39|10@0+ (0.25,-128) [-128|127.75] "m/s" XXX
 SG_ VRelLat : 45|9@0+ (0.25,-64) [-64|63.75] "m/s" XXX
 SG_ DynProp : 50|3@0+ (1,0) [0|7] "" XXX
 SG_ Class : 52|2@0+ (1,0) [0|3] "" XXX
 SG_ RCS : 63|8@0+ (0.5,-64) [-64|63.75] "dBm2" XXX

BO_ 431 ObjectData_48: 8 RADAR
 SG_ ID : 7|8@0+ (1,0) [0|255] "" XXX
 SG_ DistLong : 15|13@0+ (0.2,-500) [-500|1138.2] "m" XXX
 SG_ DistLat : 18|11@0+ (0.2,-204.6) [-204.6|204.8] "m" XXX
 SG_ VRelLong : 39|10@0+ (0.25,-128) [-128|127.75] "m/s" XXX
 SG_ VRelLat : 45|9@0+ (0.25,-64) [-64|63.75] "m/s" XXX
 SG_ DynProp : 50|3@0+ (1,0) [0|7] "" XXX
 SG_ Class : 52|2@0+ (1,0) [0|3] "" XXX
 SG_ RCS : 63|8@0+ (0.5,-64) [-64|63.75] "dBm2" XXX

BO_ 432 ObjectData_49: 8 RADAR
 SG_ ID : 7|8@0+ (1,0) [0|255] "" XXX
 SG_ DistLong : 15|13@0+ (0.2,-500) [-500|1138.2] "m" XXX
 SG_ DistLat : 18|11@0+ (0.2,-204.6) [-204.6|204.8] "m" XXX
 SG_ VRelLong : 39|10@0+ (0.25,-128) [-128|127.75] "m/s" XXX
 SG_ VRelLat : 45|9@0+ (0.25,-64) [-64|63.75] "m/s" XXX
 SG_ DynProp : 50|3@0+ (1,0) [0|7] "" XXX
 SG_ Class : 52|2@0+ (1,0) [0|3] "" XXX
 SG_ RCS : 63|8@0+ (0.5,-64) [-64|63.75] "dBm2" XXX

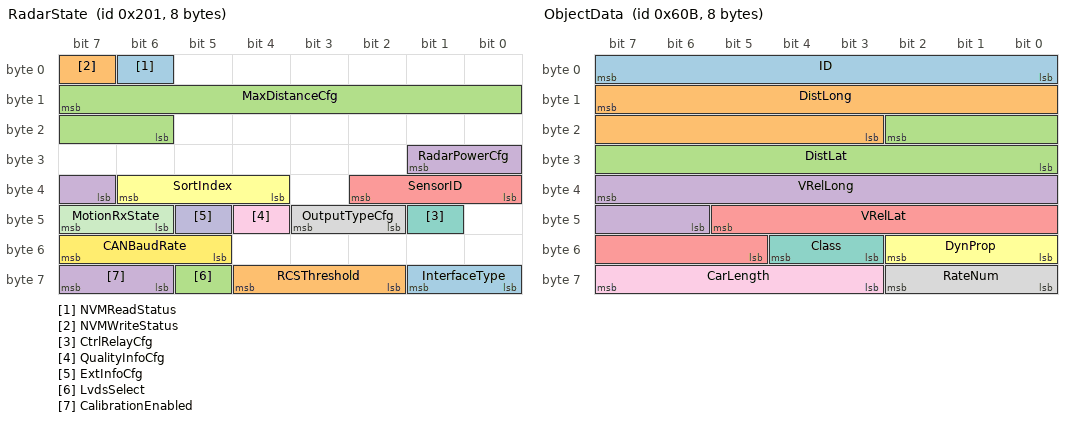
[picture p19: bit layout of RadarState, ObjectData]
BO_ 513 RadarState: 8 RADAR
 SG_ NVMReadStatus : 6|1@0+ (1,0) [0|1] "" XXX
 SG_ NVMWriteStatus : 7|1@0+ (1,0) [0|1] "" XXX
 SG_ MaxDistanceCfg : 15|10@0+ (2,0) [0|2046] "m" XXX
 SG_ RadarPowerCfg : 25|3@0+ (1,0) [0|7] "" XXX
 SG_ SensorID : 34|3@0+ (1,0) [0|7] "" XXX
 SG_ SortIndex : 38|3@0+ (1,0) [0|7] "" XXX
 SG_ CtrlRelayCfg : 41|1@0+ (1,0) [0|1] "" XXX
 SG_ OutputTypeCfg : 43|2@0+ (1,0) [0|3] "" XXX
 SG_ QualityInfoCfg : 44|1@0+ (1,0) [0|1] "" XXX
 SG_ ExtInfoCfg : 45|1@0+ (1,0) [0|1] "" XXX
 SG_ MotionRxState : 46|2@1+ (1,0) [0|3] "" XXX
 SG_ CANBaudRate : 55|3@0+ (1,0) [0|7] "" XXX
 SG_ InterfaceType : 57|2@0+ (1,0) [0|3] "" XXX
 SG_ RCSThreshold : 58|3@1+ (1,0) [0|7] "" XXX
 SG_ LvdsSelect : 61|1@0+ (1,0) [0|1] "" XXX
 SG_ CalibrationEnabled : 63|2@0+ (1,0) [0|3] "" XXX

BO_ 1546 Status: 8 RADAR
 SG_ NoOfObjects : 7|8@0+ (1,0) [0|255] "" XXX
 SG_ MeasCount : 15|16@0+ (1,0) [0|65535] "" XXX
 SG_ InterfaceVersion : 31|4@0+ (1,0) [0|15] "" XXX

BO_ 1547 ObjectData: 8 RADAR
 SG_ ID : 7|8@0+ (1,0) [0|255] "" XXX
 SG_ DistLong : 15|13@0+ (0.2,-500) [-500|1138.2] "m" XXX
 SG_ DistLat : 18|11@0+ (0.2,-204.6) [-204.6|204.8] "m" XXX
 SG_ VRelLong : 39|10@0+ (0.25,-128) [-128|127.75] "m/s" XXX
 SG_ VRelLat : 45|9@0+ (0.25,-64) [-64|63.75] "m/s" XXX
 SG_ DynProp : 50|3@0+ (1,0) [0|7] "" XXX
 SG_ Class : 52|2@0+ (1,0) [0|3] "" XXX
 SG_ RateNum : 58|3@0+ (1,0) [0|7] "" XXX
 SG_ CarLength : 63|5@0+ (0,0) [-64|63.75] "m" XXX

BO_ 1792 SoftwareInfo: 8 RADAR
 SG_ MajorRelease : 7|8@0+ (1,0) [0|255] "" XXX
 SG_ MinorRelease : 15|8@0+ (1,0) [0|255] "" XXX
 SG_ PatchLevel : 23|8@0+ (1,0) [0|255] "" XXX

CM_ BO_ 383 "Object detection and tracking information";
CM_ BO_ 384 "Object detection and tracking information";
CM_ BO_ 385 "Object detection and tracking information";
CM_ BO_ 386 "Object detection and tracking information";
CM_ BO_ 387 "Object detection and tracking information";
CM_ BO_ 388 "Object detection and tracking information";
CM_ BO_ 389 "Object detection and tracking information";
CM_ BO_ 390 "Object detection and tracking information";
CM_ BO_ 391 "Object detection and tracking information";
CM_ BO_ 392 "Object detection and tracking information";
CM_ BO_ 393 "Object detection and tracking information";
CM_ BO_ 394 "Object detection and tracking information";
CM_ BO_ 395 "Object detection and tracking information";
CM_ BO_ 396 "Object detection and tracking information";
CM_ BO_ 397 "Object detection and tracking information";
CM_ BO_ 398 "Object detection and tracking information";
CM_ BO_ 399 "Object detection and tracking information";
CM_ BO_ 400 "Object detection and tracking information";
CM_ BO_ 401 "Object detection and tracking information";
CM_ BO_ 402 "Object detection and tracking information";
CM_ BO_ 403 "Object detection and tracking information";
CM_ BO_ 404 "Object detection and tracking information";
CM_ BO_ 405 "Object detection and tracking information";
CM_ BO_ 406 "Object detection and tracking information";
CM_ BO_ 407 "Object detection and tracking information";
CM_ BO_ 408 "Object detection and tracking information";
CM_ BO_ 409 "Object detection and tracking information";
CM_ BO_ 410 "Object detection and tracking information";
CM_ BO_ 411 "Object detection and tracking information";
CM_ BO_ 412 "Object detection and tracking information";
CM_ BO_ 413 "Object detection and tracking information";
CM_ BO_ 414 "Object detection and tracking information";
CM_ BO_ 415 "Object detection and tracking information";
CM_ BO_ 416 "Object detection and tracking information";
CM_ BO_ 417 "Object detection and tracking information";
CM_ BO_ 418 "Object detection and tracking information";
CM_ BO_ 419 "Object detection and tracking information";
CM_ BO_ 420 "Object detection and tracking information";
CM_ BO_ 421 "Object detection and tracking information";
CM_ BO_ 422 "Object detection and tracking information";
CM_ BO_ 423 "Object detection and tracking information";
CM_ BO_ 424 "Object detection and tracking information";
CM_ BO_ 425 "Object detection and tracking information";
CM_ BO_ 426 "Object detection and tracking information";
CM_ BO_ 427 "Object detection and tracking information";
CM_ BO_ 428 "Object detection and tracking information";
CM_ BO_ 429 "Object detection and tracking information";
CM_ BO_ 430 "Object detection and tracking information";
CM_ BO_ 431 "Object detection and tracking information";
CM_ BO_ 432 "Object detection and tracking information";
CM_ BO_ 1547 "Object detection and tracking information";
CM_ SG_ 1547 RateNum "Target Lane Number";
VAL_ 383 DynProp 0 "moving" 1 "stationary" 2 "oncoming" 3 "crossing_left" 4 "crossing_right" 5 "unknown" 6 "stopped";
VAL_ 383 Class 0 "point" 1 "vehicle";
VAL_ 384 DynProp 0 "moving" 1 "stationary" 2 "oncoming" 3 "crossing_left" 4 "crossing_right" 5 "unknown" 6 "stopped";
VAL_ 384 Class 0 "point" 1 "vehicle";
VAL_ 385 DynProp 0 "moving" 1 "stationary" 2 "oncoming" 3 "crossing_left" 4 "crossing_right" 5 "unknown" 6 "stopped";
VAL_ 385 Class 0 "point" 1 "vehicle";
VAL_ 386 DynProp 0 "moving" 1 "stationary" 2 "oncoming" 3 "crossing_left" 4 "crossing_right" 5 "unknown" 6 "stopped";
VAL_ 386 Class 0 "point" 1 "vehicle";
VAL_ 387 DynProp 0 "moving" 1 "stationary" 2 "oncoming" 3 "crossing_left" 4 "crossing_right" 5 "unknown" 6 "stopped";
VAL_ 387 Class 0 "point" 1 "vehicle";
VAL_ 388 DynProp 0 "moving" 1 "stationary" 2 "oncoming" 3 "crossing_left" 4 "crossing_right" 5 "unknown" 6 "stopped";
VAL_ 388 Class 0 "point" 1 "vehicle";
VAL_ 389 DynProp 0 "moving" 1 "stationary" 2 "oncoming" 3 "crossing_left" 4 "crossing_right" 5 "unknown" 6 "stopped";
VAL_ 389 Class 0 "point" 1 "vehicle";
VAL_ 390 DynProp 0 "moving" 1 "stationary" 2 "oncoming" 3 "crossing_left" 4 "crossing_right" 5 "unknown" 6 "stopped";
VAL_ 390 Class 0 "point" 1 "vehicle";
VAL_ 391 DynProp 0 "moving" 1 "stationary" 2 "oncoming" 3 "crossing_left" 4 "crossing_right" 5 "unknown" 6 "stopped";
VAL_ 391 Class 0 "point" 1 "vehicle";
VAL_ 392 DynProp 0 "moving" 1 "stationary" 2 "oncoming" 3 "crossing_left" 4 "crossing_right" 5 "unknown" 6 "stopped";
VAL_ 392 Class 0 "point" 1 "vehicle";
VAL_ 393 DynProp 0 "moving" 1 "stationary" 2 "oncoming" 3 "crossing_left" 4 "crossing_right" 5 "unknown" 6 "stopped";
VAL_ 393 Class 0 "point" 1 "vehicle";
VAL_ 394 DynProp 0 "moving" 1 "stationary" 2 "oncoming" 3 "crossing_left" 4 "crossing_right" 5 "unknown" 6 "stopped";
VAL_ 394 Class 0 "point" 1 "vehicle";
VAL_ 395 DynProp 0 "moving" 1 "stationary" 2 "oncoming" 3 "crossing_left" 4 "crossing_right" 5 "unknown" 6 "stopped";
VAL_ 395 Class 0 "point" 1 "vehicle";
VAL_ 396 DynProp 0 "moving" 1 "stationary" 2 "oncoming" 3 "crossing_left" 4 "crossing_right" 5 "unknown" 6 "stopped";
VAL_ 396 Class 0 "point" 1 "vehicle";
VAL_ 397 DynProp 0 "moving" 1 "stationary" 2 "oncoming" 3 "crossing_left" 4 "crossing_right" 5 "unknown" 6 "stopped";
VAL_ 397 Class 0 "point" 1 "vehicle";
VAL_ 398 DynProp 0 "moving" 1 "stationary" 2 "oncoming" 3 "crossing_left" 4 "crossing_right" 5 "unknown" 6 "stopped";
VAL_ 398 Class 0 "point" 1 "vehicle";
VAL_ 399 DynProp 0 "moving" 1 "stationary" 2 "oncoming" 3 "crossing_left" 4 "crossing_right" 5 "unknown" 6 "stopped";
VAL_ 399 Class 0 "point" 1 "vehicle";
VAL_ 400 DynProp 0 "moving" 1 "stationary" 2 "oncoming" 3 "crossing_left" 4 "crossing_right" 5 "unknown" 6 "stopped";
VAL_ 400 Class 0 "point" 1 "vehicle";
VAL_ 401 DynProp 0 "moving" 1 "stationary" 2 "oncoming" 3 "crossing_left" 4 "crossing_right" 5 "unknown" 6 "stopped";
VAL_ 401 Class 0 "point" 1 "vehicle";
VAL_ 402 DynProp 0 "moving" 1 "stationary" 2 "oncoming" 3 "crossing_left" 4 "crossing_right" 5 "unknown" 6 "stopped";
VAL_ 402 Class 0 "point" 1 "vehicle";
VAL_ 403 DynProp 0 "moving" 1 "stationary" 2 "oncoming" 3 "crossing_left" 4 "crossing_right" 5 "unknown" 6 "stopped";
VAL_ 403 Class 0 "point" 1 "vehicle";
VAL_ 404 DynProp 0 "moving" 1 "stationary" 2 "oncoming" 3 "crossing_left" 4 "crossing_right" 5 "unknown" 6 "stopped";
VAL_ 404 Class 0 "point" 1 "vehicle";
VAL_ 405 DynProp 0 "moving" 1 "stationary" 2 "oncoming" 3 "crossing_left" 4 "crossing_right" 5 "unknown" 6 "stopped";
VAL_ 405 Class 0 "point" 1 "vehicle";
VAL_ 406 DynProp 0 "moving" 1 "stationary" 2 "oncoming" 3 "crossing_left" 4 "crossing_right" 5 "unknown" 6 "stopped";
VAL_ 406 Class 0 "point" 1 "vehicle";
VAL_ 407 DynProp 0 "moving" 1 "stationary" 2 "oncoming" 3 "crossing_left" 4 "crossing_right" 5 "unknown" 6 "stopped";
VAL_ 407 Class 0 "point" 1 "vehicle";
VAL_ 408 DynProp 0 "moving" 1 "stationary" 2 "oncoming" 3 "crossing_left" 4 "crossing_right" 5 "unknown" 6 "stopped";
VAL_ 408 Class 0 "point" 1 "vehicle";
VAL_ 409 DynProp 0 "moving" 1 "stationary" 2 "oncoming" 3 "crossing_left" 4 "crossing_right" 5 "unknown" 6 "stopped";
VAL_ 409 Class 0 "point" 1 "vehicle";
VAL_ 410 DynProp 0 "moving" 1 "stationary" 2 "oncoming" 3 "crossing_left" 4 "crossing_right" 5 "unknown" 6 "stopped";
VAL_ 410 Class 0 "point" 1 "vehicle";
VAL_ 411 DynProp 0 "moving" 1 "stationary" 2 "oncoming" 3 "crossing_left" 4 "crossing_right" 5 "unknown" 6 "stopped";
VAL_ 411 Class 0 "point" 1 "vehicle";
VAL_ 412 DynProp 0 "moving" 1 "stationary" 2 "oncoming" 3 "crossing_left" 4 "crossing_right" 5 "unknown" 6 "stopped";
VAL_ 412 Class 0 "point" 1 "vehicle";
VAL_ 413 DynProp 0 "moving" 1 "stationary" 2 "oncoming" 3 "crossing_left" 4 "crossing_right" 5 "unknown" 6 "stopped";
VAL_ 413 Class 0 "point" 1 "vehicle";
VAL_ 414 DynProp 0 "moving" 1 "stationary" 2 "oncoming" 3 "crossing_left" 4 "crossing_right" 5 "unknown" 6 "stopped";
VAL_ 414 Class 0 "point" 1 "vehicle";
VAL_ 415 DynProp 0 "moving" 1 "stationary" 2 "oncoming" 3 "crossing_left" 4 "crossing_right" 5 "unknown" 6 "stopped";
VAL_ 415 Class 0 "point" 1 "vehicle";
VAL_ 416 DynProp 0 "moving" 1 "stationary" 2 "oncoming" 3 "crossing_left" 4 "crossing_right" 5 "unknown" 6 "stopped";
VAL_ 416 Class 0 "point" 1 "vehicle";
VAL_ 417 DynProp 0 "moving" 1 "stationary" 2 "oncoming" 3 "crossing_left" 4 "crossing_right" 5 "unknown" 6 "stopped";
VAL_ 417 Class 0 "point" 1 "vehicle";
VAL_ 418 DynProp 0 "moving" 1 "stationary" 2 "oncoming" 3 "crossing_left" 4 "crossing_right" 5 "unknown" 6 "stopped";
VAL_ 418 Class 0 "point" 1 "vehicle";
VAL_ 419 DynProp 0 "moving" 1 "stationary" 2 "oncoming" 3 "crossing_left" 4 "crossing_right" 5 "unknown" 6 "stopped";
VAL_ 419 Class 0 "point" 1 "vehicle";
VAL_ 420 DynProp 0 "moving" 1 "stationary" 2 "oncoming" 3 "crossing_left" 4 "crossing_right" 5 "unknown" 6 "stopped";
VAL_ 420 Class 0 "point" 1 "vehicle";
VAL_ 421 DynProp 0 "moving" 1 "stationary" 2 "oncoming" 3 "crossing_left" 4 "crossing_right" 5 "unknown" 6 "stopped";
VAL_ 421 Class 0 "point" 1 "vehicle";
VAL_ 422 DynProp 0 "moving" 1 "stationary" 2 "oncoming" 3 "crossing_left" 4 "crossing_right" 5 "unknown" 6 "stopped";
VAL_ 422 Class 0 "point" 1 "vehicle";
VAL_ 423 DynProp 0 "moving" 1 "stationary" 2 "oncoming" 3 "crossing_left" 4 "crossing_right" 5 "unknown" 6 "stopped";
VAL_ 423 Class 0 "point" 1 "vehicle";
VAL_ 424 DynProp 0 "moving" 1 "stationary" 2 "oncoming" 3 "crossing_left" 4 "crossing_right" 5 "unknown" 6 "stopped";
VAL_ 424 Class 0 "point" 1 "vehicle";
VAL_ 425 DynProp 0 "moving" 1 "stationary" 2 "oncoming" 3 "crossing_left" 4 "crossing_right" 5 "unknown" 6 "stopped";
VAL_ 425 Class 0 "point" 1 "vehicle";
VAL_ 426 DynProp 0 "moving" 1 "stationary" 2 "oncoming" 3 "crossing_left" 4 "crossing_right" 5 "unknown" 6 "stopped";
VAL_ 426 Class 0 "point" 1 "vehicle";
VAL_ 427 DynProp 0 "moving" 1 "stationary" 2 "oncoming" 3 "crossing_left" 4 "crossing_right" 5 "unknown" 6 "stopped";
VAL_ 427 Class 0 "point" 1 "vehicle";
VAL_ 428 DynProp 0 "moving" 1 "stationary" 2 "oncoming" 3 "crossing_left" 4 "crossing_right" 5 "unknown" 6 "stopped";
VAL_ 428 Class 0 "point" 1 "vehicle";
VAL_ 429 DynProp 0 "moving" 1 "stationary" 2 "oncoming" 3 "crossing_left" 4 "crossing_right" 5 "unknown" 6 "stopped";
VAL_ 429 Class 0 "point" 1 "vehicle";
VAL_ 430 DynProp 0 "moving" 1 "stationary" 2 "oncoming" 3 "crossing_left" 4 "crossing_right" 5 "unknown" 6 "stopped";
VAL_ 430 Class 0 "point" 1 "vehicle";
VAL_ 431 DynProp 0 "moving" 1 "stationary" 2 "oncoming" 3 "crossing_left" 4 "crossing_right" 5 "unknown" 6 "stopped";
VAL_ 431 Class 0 "point" 1 "vehicle";
VAL_ 432 DynProp 0 "moving" 1 "stationary" 2 "oncoming" 3 "crossing_left" 4 "crossing_right" 5 "unknown" 6 "stopped";
VAL_ 432 Class 0 "point" 1 "vehicle";
VAL_ 513 NVMReadStatus 0 "Failed" 1 "Successful";
VAL_ 513 NVMWriteStatus 0 "Failed" 1 "Successful";
VAL_ 513 RadarPowerCfg 0 "Standard" 1 "-3dB Gain" 2 "-6dB Gain" 3 "-9dB Gain";
VAL_ 513 SortIndex 0 "No Sorting" 1 "Sort By Range" 2 "Sort By RCS";
VAL_ 513 CtrlRelayCfg 0 "Off" 1 "On";
VAL_ 513 OutputTypeCfg 0 "None" 1 "Objects" 2 "Clusters";
VAL_ 513 QualityInfoCfg 0 "Off" 1 "On";
VAL_ 513 ExtInfoCfg 0 "Off" 1 "On";
VAL_ 513 MotionRxState 0 "input ok" 1 "speed missing" 2 "yaw rate missing" 3 "speed and yaw rate missing";
VAL_ 513 CANBaudRate 0 "500K" 1 "250K" 2 "1M";
VAL_ 513 RCSThreshold 0 "Standard" 1 "High Sensitivity";
VAL_ 513 CalibrationEnabled 1 "Enabled" 2 "Initial Recovery";
VAL_ 1547 DynProp 0 "moving" 1 "stationary" 2 "oncoming" 3 "crossing_left" 4 "crossing_right" 5 "unknown" 6 "stopped";
VAL_ 1547 Class 0 "point" 1 "vehicle" 2 "large vehicle" 3 "motorcycle";
